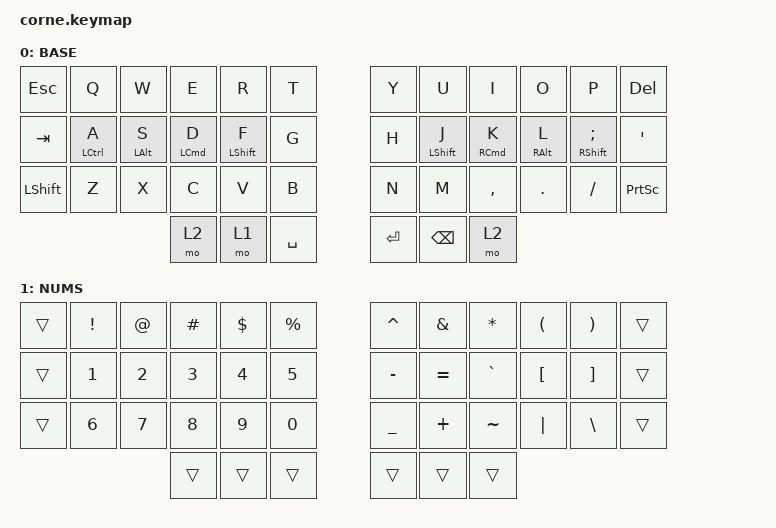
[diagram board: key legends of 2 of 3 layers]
/*
 * Copyright (c) 2020 The ZMK Contributors
 *
 * SPDX-License-Identifier: MIT
 */

#include <behaviors.dtsi>
#include <dt-bindings/zmk/bt.h>
#include <dt-bindings/zmk/keys.h>

// #include "./includes/mods.dtsi"
// #include "./includes/combos.dtsi"

/ {
    behaviors {
        bhm: balanced_homerow_mods {
            compatible = "zmk,behavior-hold-tap";
            #binding-cells = <2>;
            tapping-term-ms = <150>;    // <---[[moderate duration]]
            quick-tap-ms = <0>;
            flavor = "balanced";
            bindings = <&kp>, <&kp>;

            hold-trigger-key-positions = <13 16 14 15 16 19 20>;
        };
    };

    combos {
        compatible = "zmk,combos";

        grave {
            bindings = <&kp GRAVE>;
            key-positions = <33 34>;
        };

        undo {
            bindings = <&kp LC(Z)>;
            key-positions = <25 26>;
            slow-release;
        };

        quote {
            bindings = <&kp SINGLE_QUOTE>;
            key-positions = <22 21>;
        };

        cut {
            bindings = <&kp LC(X)>;
            key-positions = <26 27>;
            slow-release;
        };

        copy {
            bindings = <&kp LC(C)>;
            key-positions = <27 28>;
            slow-release;
        };

        paste {
            bindings = <&kp LC(V)>;
            key-positions = <28 29>;
            slow-release;
        };

        escapecombo {
            bindings = <&kp ESCAPE>;
            key-positions = <17 18>;
            slow-release;
        };
    };

    keymap {
        compatible = "zmk,keymap";

        default_layer {
            display-name = "BASE";

            // -----------------------------------------------------------------------------------------
            // |  TAB |  Q  |  W  |  E  |  R  |  T  |   |  Y  |  U   |  I  |  O  |  P  | BKSP |
            // | CTRL |  A  |  S  |  D  |  F  |  G  |   |  H  |  J   |  K  |  L  |  ;  |  '   |
            // | SHFT |  Z  |  X  |  C  |  V  |  B  |   |  N  |  M   |  ,  |  .  |  /  | ESC  |
            //                    | GUI | LWR | SPC |   | ENT | RSE  | ALT |

            bindings = <
&kp ESC         &kp Q                &kp W            &kp E                &kp R              &kp T        &kp Y      &kp U              &kp I                 &kp O             &kp P                  &kp DELETE
&kp TAB         &bhm LEFT_CONTROL A  &bhm LEFT_ALT S  &bhm LEFT_COMMAND D  &bhm LEFT_SHIFT F  &kp G        &kp H      &bhm LEFT_SHIFT J  &bhm RIGHT_COMMAND K  &bhm RIGHT_ALT L  &bhm RIGHT_SHIFT SEMI  &kp APOSTROPHE
&kp LEFT_SHIFT  &kp Z                &kp X            &kp C                &kp V              &kp B        &kp N      &kp M              &kp COMMA             &kp DOT           &kp FSLH               &kp PRINTSCREEN
                                                      &mo 2                &mo 1              &kp SPACE    &kp ENTER  &kp BACKSPACE      &mo 2
            >;
        };

        raise_layer {
            display-name = "NUMS";

            // -----------------------------------------------------------------------------------------
            // |  TAB |  !  |  @  |  #  |  $  |  %  |   |  ^  |  &  |  *  |  (  |  )  | BKSP |
            // | CTRL |     |     |     |     |     |   |  -  |  =  |  [  |  ]  |  \  |  `   |
            // | SHFT |     |     |     |     |     |   |  _  |  +  |  {  |  }  | "|" |  ~   |
            //                    | GUI |     | SPC |   | ENT |     | ALT |

            bindings = <
&trans  &kp EXCL      &kp AT        &kp HASH      &kp DLLR      &kp PRCNT       &kp CARET  &kp AMPS   &kp ASTRK  &kp LPAR          &kp RPAR           &trans
&trans  &kp NUMBER_1  &kp NUMBER_2  &kp NUMBER_3  &kp NUMBER_4  &kp NUMBER_5    &kp MINUS  &kp EQUAL  &kp GRAVE  &kp LEFT_BRACKET  &kp RIGHT_BRACKET  &trans
&trans  &kp NUMBER_6  &kp NUMBER_7  &kp NUMBER_8  &kp N9        &kp NUMBER_0    &kp UNDER  &kp PLUS   &kp TILDE  &kp PIPE          &kp BACKSLASH      &trans
                                    &trans        &trans        &trans          &trans     &trans     &trans
            >;
        };

        lower_layer {
            // -----------------------------------------------------------------------------------------
            // |  TAB |  1  |  2  |  3  |  4  |  5  |   |  6  |  7  |  8  |  9  |  0  | BKSP |
            // | BTCLR| BT1 | BT2 | BT3 | BT4 | BT5 |   | LFT | DWN |  UP | RGT |     |      |
            // | SHFT |     |     |     |     |     |   |     |     |     |     |     |      |
            //                    | GUI |     | SPC |   | ENT |     | ALT |

            display-name = "DANGER";
            bindings = <
&bt BT_CLR  &kp F1        &kp F2        &kp F3          &kp F4        &kp F5              &kp F6  &kp F7             &kp F8           &kp F9    &kp F10       &kp F11
&trans      &trans        &kp C_MUTE    &kp C_PREVIOUS  &kp C_NEXT    &kp C_PLAY_PAUSE    &trans  &trans             &trans           &trans    &kp UP_ARROW  &trans
&trans      &bt BT_SEL 0  &bt BT_SEL 1  &bt BT_SEL 2    &bt BT_SEL 3  &bt BT_SEL 4        &trans  &kp C_VOLUME_DOWN  &kp C_VOLUME_UP  &kp LEFT  &kp DOWN      &kp RIGHT
                                        &trans          &trans        &trans              &trans  &trans
            >;
        };
    };
};

&nice_view_spi { cs-gpios = <&pro_micro 0 GPIO_ACTIVE_HIGH>; };
